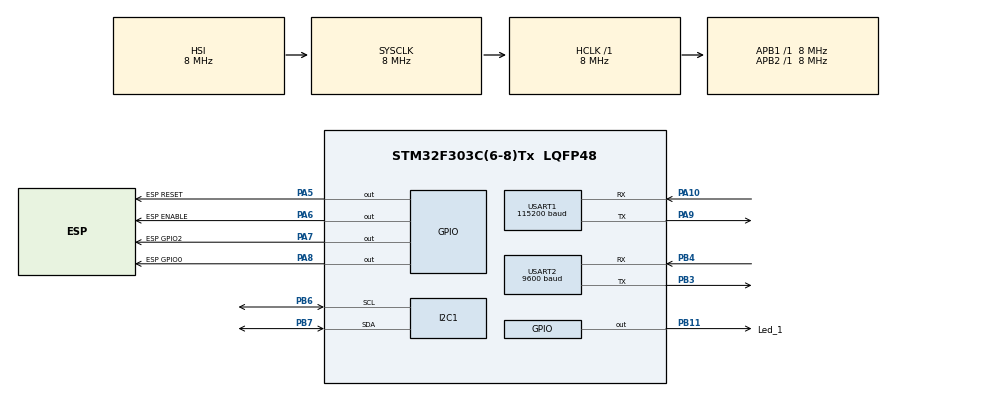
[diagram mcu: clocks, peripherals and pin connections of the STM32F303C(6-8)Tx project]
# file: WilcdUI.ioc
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Dma.Request0=USART1_RX
Dma.Request1=USART2_RX
Dma.USART1_RX.0.Direction=DMA_PERIPH_TO_MEMORY
Dma.USART1_RX.0.Instance=DMA1_Channel5
Dma.USART1_RX.0.MemDataAlignment=DMA_MDATAALIGN_BYTE
Dma.USART1_RX.0.MemInc=DMA_MINC_ENABLE
Dma.USART1_RX.0.Mode=DMA_CIRCULAR
Dma.USART1_RX.0.PeriphDataAlignment=DMA_PDATAALIGN_BYTE
Dma.USART1_RX.0.PeriphInc=DMA_PINC_DISABLE
Dma.USART1_RX.0.Priority=DMA_PRIORITY_LOW
Dma.USART2_RX.1.Direction=DMA_PERIPH_TO_MEMORY
Dma.USART2_RX.1.Instance=DMA1_Channel6
Dma.USART2_RX.1.MemDataAlignment=DMA_MDATAALIGN_BYTE
Dma.USART2_RX.1.MemInc=DMA_MINC_ENABLE
Dma.USART2_RX.1.Mode=DMA_CIRCULAR
Dma.USART2_RX.1.PeriphDataAlignment=DMA_PDATAALIGN_BYTE
Dma.USART2_RX.1.PeriphInc=DMA_PINC_DISABLE
Dma.USART2_RX.1.Priority=DMA_PRIORITY_LOW
Mcu.Family=STM32F3
Mcu.Name=STM32F303C(6-8)Tx
Mcu.Package=LQFP48
NVIC.DMA1_Channel5_IRQn=true\:0\:0\:false\:false\:true
NVIC.DMA1_Channel6_IRQn=true\:0\:0\:false\:false\:true
NVIC.PriorityGroup=NVIC_PRIORITYGROUP_4
PA10.Mode=Asynchronous
PA10.Signal=USART1_RX
PA13.Mode=Serial_Wire
PA13.Signal=SYS_JTMS-SWDIO
PA14.Mode=Serial_Wire
PA14.Signal=SYS_JTCK-SWCLK
PA5.GPIO_Label=ESP RESET
PA5.Signal=GPIO_Output
PA6.GPIO_Label=ESP ENABLE
PA6.Signal=GPIO_Output
PA7.GPIO_Label=ESP GPIO2
PA7.Signal=GPIO_Output
PA8.GPIO_Label=ESP GPIO0
PA8.Signal=GPIO_Output
PA9.Mode=Asynchronous
PA9.Signal=USART1_TX
PB11.GPIO_Label=Led_1
PB11.PinState=GPIO_PIN_RESET
PB11.Signal=GPIO_Output
PB3.Mode=Asynchronous
PB3.Signal=USART2_TX
PB4.Mode=Asynchronous
PB4.Signal=USART2_RX
PB6.Mode=I2C
PB6.Signal=I2C1_SCL
PB7.Mode=I2C
PB7.Signal=I2C1_SDA
PC14\ /\ OSC32_IN.Mode=LSE-External-Oscillator
PC14\ /\ OSC32_IN.Signal=RCC_OSC32_IN
PC15\ /\ OSC32_OUT.Mode=LSE-External-Oscillator
PC15\ /\ OSC32_OUT.Signal=RCC_OSC32_OUT
ProjectManager.HeapSize=0x200
ProjectManager.StackSize=0x400
ProjectManager.TargetToolchain=SW4STM32
RCC.AHBFreq_Value=8000000
RCC.APB1Freq_Value=8000000
RCC.APB2Freq_Value=8000000
RCC.CortexFreq_Value=8000000
RCC.HSE_VALUE=8000000
RCC.HSI_VALUE=8000000
RCC.RTCClockSelection=RCC_RTCCLKSOURCE_LSE
RCC.SYSCLKFreq_VALUE=8000000
USART1.BaudRate=115200
USART1.SwapParam=UART_ADVFEATURE_SWAP_ENABLE
USART1.VirtualMode-Asynchronous=VM_ASYNC
USART1.WordLength=WORDLENGTH_8B
USART2.BaudRate=9600
USART2.VirtualMode-Asynchronous=VM_ASYNC
USART2.WordLength=WORDLENGTH_8B
VP_RTC_VS_RTC_Activate.Mode=RTC_Enabled
VP_RTC_VS_RTC_Calendar.Mode=RTC_Calendar
board=WilcdUI

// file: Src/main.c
/**
  ******************************************************************************
  * File Name          : main.c
  * Description        : Main program body
  ******************************************************************************
  *
  * COPYRIGHT(c) 2017 STMicroelectronics
  *
  * Redistribution and use in source and binary forms, with or without modification,
  * are permitted provided that the following conditions are met:
  *   1. Redistributions of source code must retain the above copyright notice,
  *      this list of conditions and the following disclaimer.
  *   2. Redistributions in binary form must reproduce the above copyright notice,
  *      this list of conditions and the following disclaimer in the documentation
  *      and/or other materials provided with the distribution.
  *   3. Neither the name of STMicroelectronics nor the names of its contributors
  *      may be used to endorse or promote products derived from this software
  *      without specific prior written permission.
  *
  * THIS SOFTWARE IS PROVIDED BY THE COPYRIGHT HOLDERS AND CONTRIBUTORS "AS IS"
  * AND ANY EXPRESS OR IMPLIED WARRANTIES, INCLUDING, BUT NOT LIMITED TO, THE
  * IMPLIED WARRANTIES OF MERCHANTABILITY AND FITNESS FOR A PARTICULAR PURPOSE ARE
  * DISCLAIMED. IN NO EVENT SHALL THE COPYRIGHT HOLDER OR CONTRIBUTORS BE LIABLE
  * FOR ANY DIRECT, INDIRECT, INCIDENTAL, SPECIAL, EXEMPLARY, OR CONSEQUENTIAL
  * DAMAGES (INCLUDING, BUT NOT LIMITED TO, PROCUREMENT OF SUBSTITUTE GOODS OR
  * SERVICES; LOSS OF USE, DATA, OR PROFITS; OR BUSINESS INTERRUPTION) HOWEVER
  * CAUSED AND ON ANY THEORY OF LIABILITY, WHETHER IN CONTRACT, STRICT LIABILITY,
  * OR TORT (INCLUDING NEGLIGENCE OR OTHERWISE) ARISING IN ANY WAY OUT OF THE USE
  * OF THIS SOFTWARE, EVEN IF ADVISED OF THE POSSIBILITY OF SUCH DAMAGE.
  *
  ******************************************************************************
  */
#include "main.h"
#include "stm32f3xx_hal.h"
#include "dma.h"
#include "i2c.h"
#include "rtc.h"
#include "usart.h"
#include "gpio.h"

/* USER CODE BEGIN PV */
/* Private variables ---------------------------------------------------------*/

/* USER CODE END PV */

void SystemClock_Config(void);
void Error_Handler(void);

/* USER CODE BEGIN PFP */
/* Private function prototypes -----------------------------------------------*/

/* USER CODE END PFP */

int main(void)
{

  /* MCU Configuration----------------------------------------------------------*/

  /* Reset of all peripherals, Initializes the Flash interface and the Systick. */
  HAL_Init();

  /* Configure the system clock */
  SystemClock_Config();

  /* Initialize all configured peripherals */
  MX_GPIO_Init();
  MX_DMA_Init();
  MX_I2C1_Init();
  MX_RTC_Init();
  MX_USART1_UART_Init();
  MX_USART2_UART_Init();

  /* USER CODE BEGIN 2 */

  HAL_GPIO_WritePin(Led_1_GPIO_Port, Led_1_Pin, GPIO_PIN_RESET);
  Display_Init();
  ESP_Init();
  HAL_GPIO_WritePin(Led_1_GPIO_Port, Led_1_Pin, GPIO_PIN_SET);

  /* USER CODE END 2 */

  /* Infinite loop */
  /* USER CODE BEGIN WHILE */
  while (1)
  {
	  uint8_t buf[ESP_BUF_SIZE];
	  int16_t len;
	  if ((len = ESP_TCP_ReadLine(buf)) > 0) {
		  HAL_UART_Transmit(&huart2, buf, len, 1000);
		  HAL_UART_Transmit(&huart2, "\r\n", 2, 1000);
		  Display_Strn(buf, len);
	  } else if (len == -1 && (len = ESP_ReadLine(buf)) != 0) {
		  HAL_UART_Transmit(&huart2, buf, len, 1000);
		  HAL_UART_Transmit(&huart2, "\r\n", 2, 1000);
		  Display_Strn(buf, len);
	  }
	  /*uint8_t chr;
	  if (HAL_UART_Receive(&huart1, &chr, 1, 1000) != HAL_OK) {
		  continue;
	  }
	  HAL_GPIO_TogglePin(GPIOE, GPIO_PIN_9);
	  if (HAL_GPIO_ReadPin(GPIOE, GPIO_PIN_9) == GPIO_PIN_SET) {
		  chr = '1';
	  } else {
		  chr = '0';
	  }
	  HAL_UART_Transmit(&huart1, &chr, 1, 1000);
	  Display_Char(chr);*/
  /* USER CODE END WHILE */

  }

}

/** System Clock Configuration
*/
void SystemClock_Config(void)
{

  RCC_OscInitTypeDef RCC_OscInitStruct;
  RCC_ClkInitTypeDef RCC_ClkInitStruct;
  RCC_PeriphCLKInitTypeDef PeriphClkInit;

    /**Initializes the CPU, AHB and APB busses clocks
    */
  RCC_OscInitStruct.OscillatorType = RCC_OSCILLATORTYPE_HSI|RCC_OSCILLATORTYPE_LSE;
  RCC_OscInitStruct.LSEState = RCC_LSE_ON;
  RCC_OscInitStruct.HSIState = RCC_HSI_ON;
  RCC_OscInitStruct.HSICalibrationValue = 16;
  RCC_OscInitStruct.PLL.PLLState = RCC_PLL_NONE;
  if (HAL_RCC_OscConfig(&RCC_OscInitStruct) != HAL_OK)
  {
    Error_Handler();
  }

    /**Initializes the CPU, AHB and APB busses clocks
    */
  RCC_ClkInitStruct.ClockType = RCC_CLOCKTYPE_HCLK|RCC_CLOCKTYPE_SYSCLK
                              |RCC_CLOCKTYPE_PCLK1|RCC_CLOCKTYPE_PCLK2;
  RCC_ClkInitStruct.SYSCLKSource = RCC_SYSCLKSOURCE_HSI;
  RCC_ClkInitStruct.AHBCLKDivider = RCC_SYSCLK_DIV1;
  RCC_ClkInitStruct.APB1CLKDivider = RCC_HCLK_DIV1;
  RCC_ClkInitStruct.APB2CLKDivider = RCC_HCLK_DIV1;

  if (HAL_RCC_ClockConfig(&RCC_ClkInitStruct, FLASH_LATENCY_0) != HAL_OK)
  {
    Error_Handler();
  }

  PeriphClkInit.PeriphClockSelection = RCC_PERIPHCLK_USART1|RCC_PERIPHCLK_I2C1
                              |RCC_PERIPHCLK_RTC;
  PeriphClkInit.Usart1ClockSelection = RCC_USART1CLKSOURCE_PCLK1;
  PeriphClkInit.I2c1ClockSelection = RCC_I2C1CLKSOURCE_HSI;
  PeriphClkInit.RTCClockSelection = RCC_RTCCLKSOURCE_LSE;
  if (HAL_RCCEx_PeriphCLKConfig(&PeriphClkInit) != HAL_OK)
  {
    Error_Handler();
  }

    /**Configure LSE Drive Capability
    */
  __HAL_RCC_LSEDRIVE_CONFIG(RCC_LSEDRIVE_LOW);

    /**Configure the Systick interrupt time
    */
  HAL_SYSTICK_Config(HAL_RCC_GetHCLKFreq()/1000);

    /**Configure the Systick
    */
  HAL_SYSTICK_CLKSourceConfig(SYSTICK_CLKSOURCE_HCLK);

  /* SysTick_IRQn interrupt configuration */
  HAL_NVIC_SetPriority(SysTick_IRQn, 0, 0);
}

void Error_Handler(void)
{
  while(1)
  {
  }
}

/************************ (C) COPYRIGHT STMicroelectronics *****END OF FILE****/
